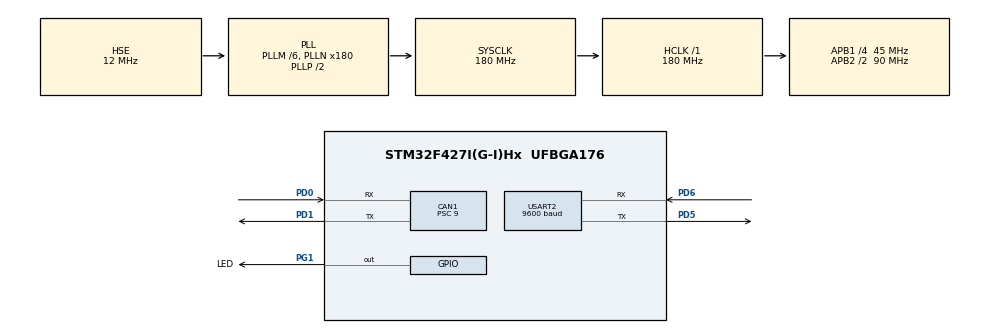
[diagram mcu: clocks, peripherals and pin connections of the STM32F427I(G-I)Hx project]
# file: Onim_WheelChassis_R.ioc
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CAN1.ABOM=ENABLE
CAN1.BS1=CAN_BS1_2TQ
CAN1.BS2=CAN_BS2_2TQ
CAN1.CalculateBaudRate=1000000
CAN1.CalculateTimeBit=1000
CAN1.CalculateTimeQuantum=200.0
CAN1.Prescaler=9
Dma.Request0=USART2_RX
Dma.Request1=USART2_TX
Dma.USART2_RX.0.Direction=DMA_PERIPH_TO_MEMORY
Dma.USART2_RX.0.FIFOMode=DMA_FIFOMODE_DISABLE
Dma.USART2_RX.0.Instance=DMA1_Stream5
Dma.USART2_RX.0.MemDataAlignment=DMA_MDATAALIGN_BYTE
Dma.USART2_RX.0.MemInc=DMA_MINC_ENABLE
Dma.USART2_RX.0.Mode=DMA_NORMAL
Dma.USART2_RX.0.PeriphDataAlignment=DMA_PDATAALIGN_BYTE
Dma.USART2_RX.0.PeriphInc=DMA_PINC_DISABLE
Dma.USART2_RX.0.Priority=DMA_PRIORITY_LOW
Dma.USART2_TX.1.Direction=DMA_MEMORY_TO_PERIPH
Dma.USART2_TX.1.FIFOMode=DMA_FIFOMODE_DISABLE
Dma.USART2_TX.1.Instance=DMA1_Stream6
Dma.USART2_TX.1.MemDataAlignment=DMA_MDATAALIGN_BYTE
Dma.USART2_TX.1.MemInc=DMA_MINC_ENABLE
Dma.USART2_TX.1.Mode=DMA_NORMAL
Dma.USART2_TX.1.PeriphDataAlignment=DMA_PDATAALIGN_BYTE
Dma.USART2_TX.1.PeriphInc=DMA_PINC_DISABLE
Dma.USART2_TX.1.Priority=DMA_PRIORITY_LOW
FREERTOS.Queues01=UartRx_Queue,16,Uart_RxFrame_t,0,Dynamic,NULL,NULL
FREERTOS.Tasks01=Uart_Task,24,128,Start_Uart_Task,As weak,NULL,Dynamic,NULL,NULL;MoControl_Task,25,128,Start_MoControl_Task,As weak,NULL,Dynamic,NULL,NULL;CAN_Task,8,128,Start_CAN_Task,As weak,NULL,Dynamic,NULL,NULL
Mcu.Family=STM32F4
Mcu.Name=STM32F427I(G-I)Hx
Mcu.Package=UFBGA176
NVIC.CAN1_RX0_IRQn=true\:5\:0\:false\:false\:true\:true\:true\:true\:true
NVIC.CAN1_RX1_IRQn=true\:5\:0\:false\:false\:true\:true\:true\:true\:true
NVIC.DMA1_Stream5_IRQn=true\:5\:0\:false\:false\:true\:true\:false\:true\:true
NVIC.DMA1_Stream6_IRQn=true\:5\:0\:false\:false\:true\:true\:false\:true\:true
NVIC.PriorityGroup=NVIC_PRIORITYGROUP_4
NVIC.TIM1_UP_TIM10_IRQn=true\:15\:0\:false\:false\:true\:false\:false\:true\:true
NVIC.TimeBase=TIM1_UP_TIM10_IRQn
NVIC.TimeBaseIP=TIM1
NVIC.USART2_IRQn=true\:5\:0\:false\:false\:true\:true\:false\:true\:true
PA13.Mode=Serial_Wire
PA13.Signal=SYS_JTMS-SWDIO
PA14.Mode=Serial_Wire
PA14.Signal=SYS_JTCK-SWCLK
PD0.Mode=CAN_Activate
PD0.Signal=CAN1_RX
PD1.Mode=CAN_Activate
PD1.Signal=CAN1_TX
PD5.Mode=Asynchronous
PD5.Signal=USART2_TX
PD6.Mode=Asynchronous
PD6.Signal=USART2_RX
PG1.GPIO_Label=LED
PG1.PinState=GPIO_PIN_SET
PG1.Signal=GPIO_Output
PH0/OSC_IN.Mode=HSE-External-Oscillator
PH0/OSC_IN.Signal=RCC_OSC_IN
PH1/OSC_OUT.Mode=HSE-External-Oscillator
PH1/OSC_OUT.Signal=RCC_OSC_OUT
ProjectManager.HeapSize=0x200
ProjectManager.StackSize=0x400
ProjectManager.TargetToolchain=CMake
RCC.48MHZClocksFreq_Value=90000000
RCC.AHBFreq_Value=180000000
RCC.APB1CLKDivider=RCC_HCLK_DIV4
RCC.APB1Freq_Value=45000000
RCC.APB1TimFreq_Value=90000000
RCC.APB2CLKDivider=RCC_HCLK_DIV2
RCC.APB2Freq_Value=90000000
RCC.APB2TimFreq_Value=180000000
RCC.CortexFreq_Value=180000000
RCC.HCLKFreq_Value=180000000
RCC.HSE_VALUE=12000000
RCC.HSI_VALUE=16000000
RCC.LSE_VALUE=32768
RCC.PLLM=6
RCC.PLLN=180
RCC.PLLSourceVirtual=RCC_PLLSOURCE_HSE
RCC.SYSCLKFreq_VALUE=180000000
RCC.SYSCLKSource=RCC_SYSCLKSOURCE_PLLCLK
RCC.VCOOutputFreq_Value=360000000
USART2.BaudRate=9600
USART2.VirtualMode=VM_ASYNC
VP_FREERTOS_VS_CMSIS_V2.Mode=CMSIS_V2
VP_SYS_VS_tim1.Mode=TIM1
board=custom

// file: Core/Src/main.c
/* USER CODE BEGIN Header */
/**
  ******************************************************************************
  * @file           : main.c
  * @brief          : Main program body
  ******************************************************************************
  * @attention
  *
  * Copyright (c) 2026 STMicroelectronics.
  * All rights reserved.
  *
  * This software is licensed under terms that can be found in the LICENSE file
  * in the root directory of this software component.
  * If no LICENSE file comes with this software, it is provided AS-IS.
  *
  ******************************************************************************
  */
/* USER CODE END Header */
#include "main.h"
#include "cmsis_os.h"
#include "can.h"
#include "dma.h"
#include "usart.h"
#include "gpio.h"

/* USER CODE BEGIN Includes */

#include "dvc_DMMotor.h"
#include "drv_can.h"
#include "My_UART.h"
#include "Chassis.h"

extern void CAN1_Rx_Callback(Struct_CAN_Rx_Buffer *Rx_Buffer);

/* USER CODE END Includes */

void SystemClock_Config(void);
void MX_FREERTOS_Init(void);

int main(void)
{

  /* MCU Configuration--------------------------------------------------------*/

  /* Reset of all peripherals, Initializes the Flash interface and the Systick. */
  HAL_Init();

  /* Configure the system clock */
  SystemClock_Config();

  /* Initialize all configured peripherals */
  MX_GPIO_Init();
  MX_DMA_Init();
  MX_CAN1_Init();
  MX_USART2_UART_Init();
  /* USER CODE BEGIN 2 */
  CAN_Init(&hcan1, CAN1_Rx_Callback);
  CAN_Filter_Mask_Config(&hcan1, CAN_FILTER(0) | CAN_FIFO_0 | CAN_STDID | CAN_DATA_TYPE, 0x200, 0x700);
  /* USER CODE END 2 */

  /* Init scheduler */
  osKernelInitialize();  /* Call init function for freertos objects (in cmsis_os2.c) */
  MX_FREERTOS_Init();

  /* Start scheduler */
  osKernelStart();

  /* We should never get here as control is now taken by the scheduler */

  /* Infinite loop */
  while (1)
  {
  }

}

void SystemClock_Config(void)
{
  RCC_OscInitTypeDef RCC_OscInitStruct = {0};
  RCC_ClkInitTypeDef RCC_ClkInitStruct = {0};

  /** Configure the main internal regulator output voltage
  */
  __HAL_RCC_PWR_CLK_ENABLE();
  __HAL_PWR_VOLTAGESCALING_CONFIG(PWR_REGULATOR_VOLTAGE_SCALE1);

  /** Initializes the RCC Oscillators according to the specified parameters
  * in the RCC_OscInitTypeDef structure.
  */
  RCC_OscInitStruct.OscillatorType = RCC_OSCILLATORTYPE_HSE;
  RCC_OscInitStruct.HSEState = RCC_HSE_ON;
  RCC_OscInitStruct.PLL.PLLState = RCC_PLL_ON;
  RCC_OscInitStruct.PLL.PLLSource = RCC_PLLSOURCE_HSE;
  RCC_OscInitStruct.PLL.PLLM = 6;
  RCC_OscInitStruct.PLL.PLLN = 180;
  RCC_OscInitStruct.PLL.PLLP = RCC_PLLP_DIV2;
  RCC_OscInitStruct.PLL.PLLQ = 4;
  if (HAL_RCC_OscConfig(&RCC_OscInitStruct) != HAL_OK)
  {
    Error_Handler();
  }

  /** Activate the Over-Drive mode
  */
  if (HAL_PWREx_EnableOverDrive() != HAL_OK)
  {
    Error_Handler();
  }

  /** Initializes the CPU, AHB and APB buses clocks
  */
  RCC_ClkInitStruct.ClockType = RCC_CLOCKTYPE_HCLK|RCC_CLOCKTYPE_SYSCLK
                              |RCC_CLOCKTYPE_PCLK1|RCC_CLOCKTYPE_PCLK2;
  RCC_ClkInitStruct.SYSCLKSource = RCC_SYSCLKSOURCE_PLLCLK;
  RCC_ClkInitStruct.AHBCLKDivider = RCC_SYSCLK_DIV1;
  RCC_ClkInitStruct.APB1CLKDivider = RCC_HCLK_DIV4;
  RCC_ClkInitStruct.APB2CLKDivider = RCC_HCLK_DIV2;

  if (HAL_RCC_ClockConfig(&RCC_ClkInitStruct, FLASH_LATENCY_5) != HAL_OK)
  {
    Error_Handler();
  }
}

void HAL_TIM_PeriodElapsedCallback(TIM_HandleTypeDef *htim)
{
  if (htim->Instance == TIM1)
  {
    HAL_IncTick();
  }
}

void Error_Handler(void)
{
  __disable_irq();
  while (1)
  {
  }
}

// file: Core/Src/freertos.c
/* USER CODE BEGIN Header */
/**
  ******************************************************************************
  * File Name          : freertos.c
  * Description        : Code for freertos applications
  ******************************************************************************
  * @attention
  *
  * Copyright (c) 2026 STMicroelectronics.
  * All rights reserved.
  *
  * This software is licensed under terms that can be found in the LICENSE file
  * in the root directory of this software component.
  * If no LICENSE file comes with this software, it is provided AS-IS.
  *
  ******************************************************************************
  */
/* USER CODE END Header */

#include "FreeRTOS.h"
#include "task.h"
#include "main.h"
#include "cmsis_os.h"

/* USER CODE BEGIN Includes */

#include "My_UART.h"

/* USER CODE END Includes */

/* Definitions for Uart_Task */
osThreadId_t Uart_TaskHandle;
const osThreadAttr_t Uart_Task_attributes = {
  .name = "Uart_Task",
  .stack_size = 128 * 4,
  .priority = (osPriority_t) osPriorityNormal,
};
/* Definitions for MoControl_Task */
osThreadId_t MoControl_TaskHandle;
const osThreadAttr_t MoControl_Task_attributes = {
  .name = "MoControl_Task",
  .stack_size = 128 * 4,
  .priority = (osPriority_t) osPriorityNormal1,
};
/* Definitions for CAN_Task */
osThreadId_t CAN_TaskHandle;
const osThreadAttr_t CAN_Task_attributes = {
  .name = "CAN_Task",
  .stack_size = 128 * 4,
  .priority = (osPriority_t) osPriorityLow,
};
/* Definitions for UartRx_Queue */
osMessageQueueId_t UartRx_QueueHandle;
const osMessageQueueAttr_t UartRx_Queue_attributes = {
  .name = "UartRx_Queue"
};

void Start_Uart_Task(void *argument);
void Start_MoControl_Task(void *argument);
void Start_CAN_Task(void *argument);

void MX_FREERTOS_Init(void); /* (MISRA C 2004 rule 8.1) */

void MX_FREERTOS_Init(void) {

  /* Create the queue(s) */
  /* creation of UartRx_Queue */
  UartRx_QueueHandle = osMessageQueueNew (16, sizeof(Uart_RxFrame_t), &UartRx_Queue_attributes);

  /* Create the thread(s) */
  /* creation of Uart_Task */
  Uart_TaskHandle = osThreadNew(Start_Uart_Task, NULL, &Uart_Task_attributes);

  /* creation of MoControl_Task */
  MoControl_TaskHandle = osThreadNew(Start_MoControl_Task, NULL, &MoControl_Task_attributes);

  /* creation of CAN_Task */
  CAN_TaskHandle = osThreadNew(Start_CAN_Task, NULL, &CAN_Task_attributes);

}

__weak void Start_Uart_Task(void *argument)
{
  for(;;)
  {
    osDelay(1);
  }
}

__weak void Start_MoControl_Task(void *argument)
{
  for(;;)
  {
    osDelay(1);
  }
}

__weak void Start_CAN_Task(void *argument)
{
  for(;;)
  {
    osDelay(1);
  }
}
